# EFR32FG25A221F1920IM56 register map
Vendor: Silicon Labs; Series: EFR32; File version: B
Registers are 32-bit, read-write, reset 0x0 unless marked. A register's access mark holds for its fields unless they carry their own. Offsets are from the block's base; [hi:lo] are bit positions; 'fields as' and 'values as' point back to an identical list.

## SYSRTC0_NS — SYSRTC0_NS Registers
Base 0x500B0000
Same registers: SYSRTC0_S 0x400B0000
0x00 IPVERSION ro reset 0x1
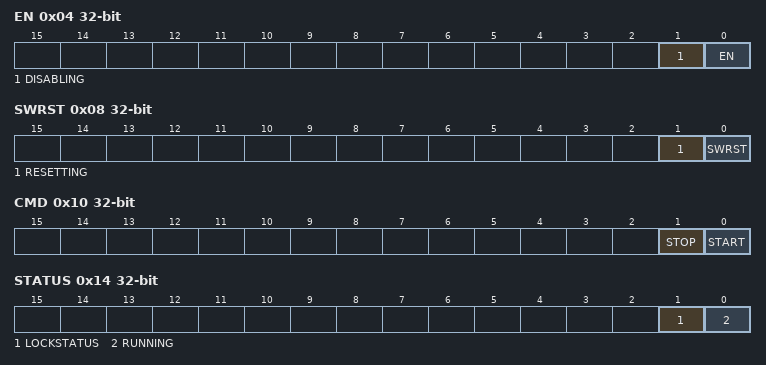
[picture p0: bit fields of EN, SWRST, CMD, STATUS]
0x04 EN
  [1] DISABLING ro — Disablement busy status
  [0] EN — SYSRTC Enable
0x08 SWRST
  [1] RESETTING ro — Software reset busy status
  [0] SWRST wo — Software reset command
0x0C CFG
  [0] DEBUGRUN — Debug Mode Run Enable
    0=DISABLE (SYSRTC is frozen in debug mode); 1=ENABLE (SYSRTC is running in debug mode)
0x10 CMD wo
  [1] STOP — Stop SYSRTC
  [0] START — Start SYSRTC
0x14 STATUS ro
  [1] LOCKSTATUS
    0=UNLOCKED (SYSRTC registers are unlocked); 1=LOCKED (SYSRTC registers are locked)
  [0] RUNNING — SYSRTC running status
0x18 CNT
  [31:0] CNT — Counter Value
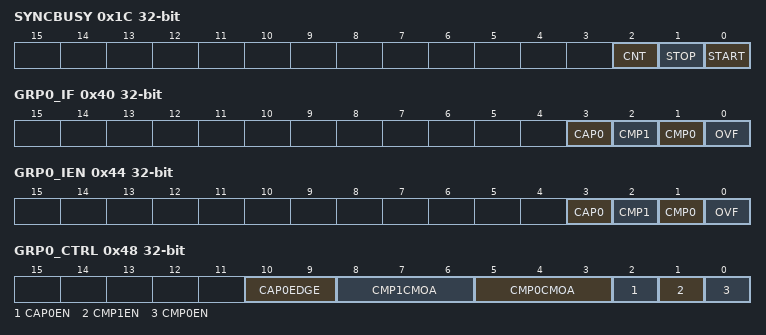
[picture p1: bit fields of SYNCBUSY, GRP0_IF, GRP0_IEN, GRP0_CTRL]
0x1C SYNCBUSY ro
  [2] CNT — Sync busy for CNT bitfield
  [1] STOP — Sync busy for STOP bitfield
  [0] START — Sync busy for START bitfield
0x20 LOCK wo
  [15:0] LOCKKEY — Configuration Lock Key
    0x4776=UNLOCK (Write to unlock SYSRTC lockable registers)
0x40 GRP0_IF
  [3] CAP0 — Capture 0 Interrupt Flag
  [2] CMP1 — Compare 1 Interrupt Flag
  [1] CMP0 — Compare 0 Interrupt Flag
  [0] OVF — Overflow Interrupt Flag
0x44 GRP0_IEN
  [3] CAP0 — Capture 0 Interrupt Enable
  [2] CMP1 — Compare 1 Interrupt Enable
  [1] CMP0 — Compare 0 Interrupt Enable
  [0] OVF — Overflow Interrupt Enable
0x48 GRP0_CTRL
  [10:9] CAP0EDGE — Capture 0 Edge Select
    0=RISING (Rising edges detected); 1=FALLING (Falling edges detected); 2=BOTH (Both edges detected)
  [8:6] CMP1CMOA — Compare 1 Compare Match Output Action
    0=CLEAR (Cleared on the next cycle); 1=SET (Set on the next cycle); 2=PULSE (Set on the next cycle, cleared on the cycle after); 3=TOGGLE (Inverted on the next cycle); 4=CMPIF (Export this channel's CMP IF)
  [5:3] CMP0CMOA — Compare 0 Compare Match Output Action
    values as CMP1CMOA
  [2] CAP0EN — Capture 0 Enable
  [1] CMP1EN — Compare 1 Enable
  [0] CMP0EN — Compare 0 Enable
0x4C GRP0_CMP0VALUE
  [31:0] CMP0VALUE — Compare 0 Value
0x50 GRP0_CMP1VALUE
  [31:0] CMP1VALUE — Compare 1 Value
0x54 GRP0_CAP0VALUE ro
  [31:0] CAP0VALUE — Capture 0 Value
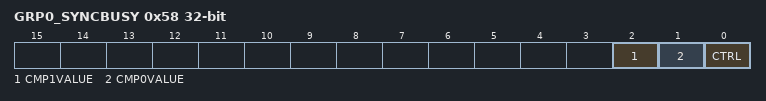
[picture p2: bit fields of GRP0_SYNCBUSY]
0x58 GRP0_SYNCBUSY ro
  [2] CMP1VALUE — Sync busy for CMP1VALUE register
  [1] CMP0VALUE — Sync busy for CMP0VALUE register
  [0] CTRL — Sync busy for CTRL register

## ULFRCO_NS — ULFRCO_NS Registers
Base 0x50028000
Same registers: ULFRCO_S 0x40028000
0x00 IPVERSION ro reset 0x1
  [31:0] IPVERSION — ULFRCO IP version
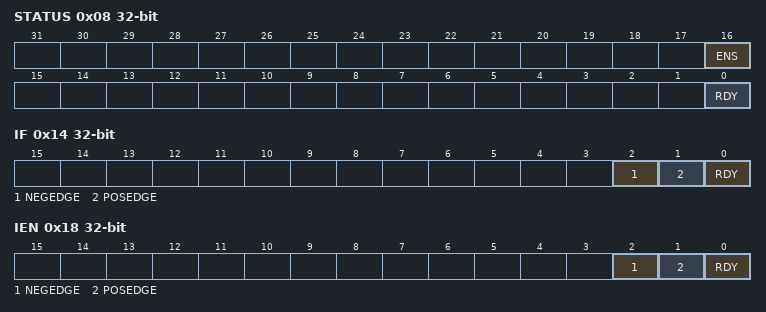
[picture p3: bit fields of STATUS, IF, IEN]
0x08 STATUS ro
  [16] ENS — Enable Status
  [0] RDY — Ready Status
0x14 IF
  [2] NEGEDGE — Negative Edge Interrupt Flag
  [1] POSEDGE — Positive Edge Interrupt Flag
  [0] RDY — Ready Interrupt Flag
0x18 IEN
  [2] NEGEDGE — Enable Negative Edge Interrupt
  [1] POSEDGE — Enable Positive Edge Interrupt
  [0] RDY — Enable Ready Interrupt

## USBPLL0_NS — USBPLL0_NS Registers
Base 0x57004000
Same registers: USBPLL0_S 0x47004000
0x00 IPVERSION ro reset 0x1
  [31:0] IPVERSION — IP Version ID
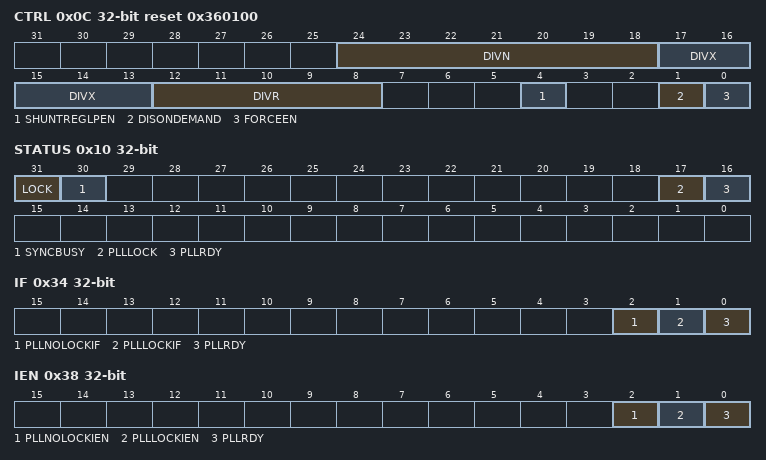
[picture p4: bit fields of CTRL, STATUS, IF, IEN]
0x0C CTRL reset 0x360100 — Control
  [24:18] DIVN — Divider N
  [17:13] DIVX — Divider X
  [12:8] DIVR — Divider R
  [4] SHUNTREGLPEN — Shunt Regulator LP Enable
  [1] DISONDEMAND — Disable on Demand
  [0] FORCEEN — Force Enable
0x10 STATUS ro
  [31] LOCK — Locks out registers
    0=UNLOCKED (Configuration is unlocked); 1=LOCKED (Configuration is locked)
  [30] SYNCBUSY
  [17] PLLLOCK — USBPLL is locked
  [16] PLLRDY — USBPLL Ready
0x1C DCOCTRL reset 0x60E00 — DAC Controlled Oscillator
  [9] DCOBIASHALF — DCO Half bias
    0=DISABLE; 1=ENABLE
0x30 LOCK wo reset 0x580E — Lock PLL from APBIF access
  [15:0] LOCKKEY — Configuration Lock Key
    0x580E=UNLOCK (Write this value to unlock)
0x34 IF — Interrupt flag
  [2] PLLNOLOCKIF — USBPLL Loss of Lock Interrupt Flag
  [1] PLLLOCKIF — USBPLL Lock Interrupt Flag
  [0] PLLRDY — USBPLL Ready Interrupt Flag
0x38 IEN — Interrupt enable
  [2] PLLNOLOCKIEN — USBPLL Loss of Lock Interrupt Enable
  [1] PLLLOCKIEN — USBPLL Lock Interrupt Enable
  [0] PLLRDY — USBPLL Ready Interrupt Enable
